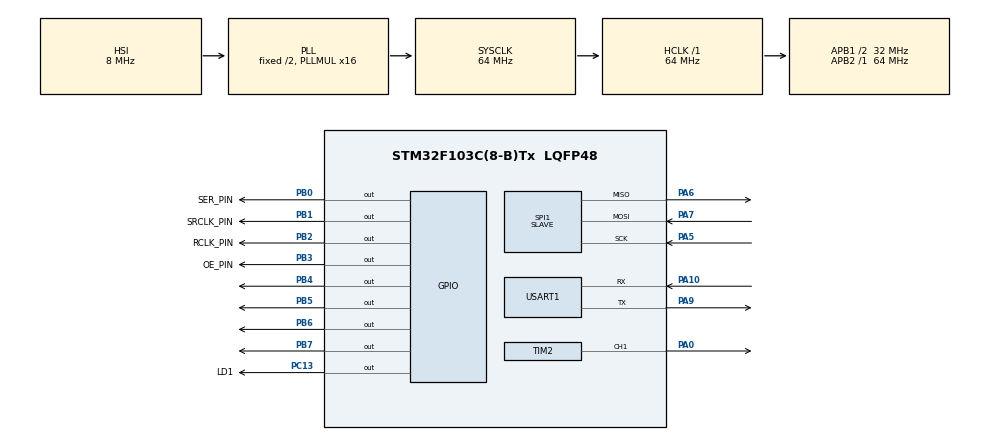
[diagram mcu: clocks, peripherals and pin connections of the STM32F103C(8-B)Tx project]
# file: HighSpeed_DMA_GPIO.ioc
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Dma.Request0=TIM2_UP
Dma.TIM2_UP.0.Direction=DMA_PERIPH_TO_MEMORY
Dma.TIM2_UP.0.Instance=DMA1_Channel2
Dma.TIM2_UP.0.MemDataAlignment=DMA_MDATAALIGN_WORD
Dma.TIM2_UP.0.MemInc=DMA_MINC_ENABLE
Dma.TIM2_UP.0.Mode=DMA_CIRCULAR
Dma.TIM2_UP.0.PeriphDataAlignment=DMA_PDATAALIGN_WORD
Dma.TIM2_UP.0.PeriphInc=DMA_PINC_DISABLE
Dma.TIM2_UP.0.Priority=DMA_PRIORITY_LOW
Mcu.Family=STM32F1
Mcu.Name=STM32F103C(8-B)Tx
Mcu.Package=LQFP48
Mcu.UserConstants=TIM1_PERIOD,512-1;TIM1_PRESCALER,0;TIM2_PERIOD,512-2;TIM2_PRESCALER,0
NVIC.DMA1_Channel2_IRQn=true\:0\:0\:false\:false\:true\:false\:true\:true
NVIC.PriorityGroup=NVIC_PRIORITYGROUP_4
PA0-WKUP.Signal=S_TIM2_CH1_ETR
PA10.Mode=Asynchronous
PA10.Signal=USART1_RX
PA13.Mode=Serial_Wire
PA13.Signal=SYS_JTMS-SWDIO
PA14.Mode=Serial_Wire
PA14.Signal=SYS_JTCK-SWCLK
PA5.Mode=Full_Duplex_Slave
PA5.Signal=SPI1_SCK
PA6.Mode=Full_Duplex_Slave
PA6.Signal=SPI1_MISO
PA7.Mode=Full_Duplex_Slave
PA7.Signal=SPI1_MOSI
PA9.Mode=Asynchronous
PA9.Signal=USART1_TX
PB0.GPIO_Label=SER_PIN
PB0.GPIO_Speed=GPIO_SPEED_FREQ_HIGH
PB0.Signal=GPIO_Output
PB1.GPIO_Label=SRCLK_PIN
PB1.GPIO_Speed=GPIO_SPEED_FREQ_HIGH
PB1.Signal=GPIO_Output
PB2.GPIO_Label=RCLK_PIN
PB2.GPIO_Speed=GPIO_SPEED_FREQ_HIGH
PB2.Signal=GPIO_Output
PB3.GPIO_Label=OE_PIN
PB3.GPIO_Speed=GPIO_SPEED_FREQ_HIGH
PB3.Signal=GPIO_Output
PB4.Signal=GPIO_Output
PB5.Signal=GPIO_Output
PB6.Signal=GPIO_Output
PB7.Signal=GPIO_Output
PC13-TAMPER-RTC.GPIO_Label=LD1
PC13-TAMPER-RTC.Signal=GPIO_Output
PD0-OSC_IN.Mode=HSE-External-Oscillator
PD0-OSC_IN.Signal=RCC_OSC_IN
PD1-OSC_OUT.Mode=HSE-External-Oscillator
PD1-OSC_OUT.Signal=RCC_OSC_OUT
ProjectManager.HeapSize=0x200
ProjectManager.StackSize=0x400
ProjectManager.TargetToolchain=STM32CubeIDE
RCC.AHBFreq_Value=64000000
RCC.APB1CLKDivider=RCC_HCLK_DIV2
RCC.APB1Freq_Value=32000000
RCC.APB1TimFreq_Value=64000000
RCC.APB2Freq_Value=64000000
RCC.APB2TimFreq_Value=64000000
RCC.HCLKFreq_Value=64000000
RCC.HSEDivPLL=RCC_HSE_PREDIV_DIV2
RCC.HSE_VALUE=16000000
RCC.PLLMUL=RCC_PLL_MUL16
RCC.SYSCLKFreq_VALUE=64000000
RCC.SYSCLKSource=RCC_SYSCLKSOURCE_PLLCLK
RCC.USBFreq_Value=64000000
SH.S_TIM2_CH1_ETR.0=TIM2_CH1,Output Compare1 CH1
SPI1.Direction=SPI_DIRECTION_2LINES
SPI1.Mode=SPI_MODE_SLAVE
SPI1.VirtualType=VM_SLAVE
TIM2.AutoReloadPreload=TIM_AUTORELOAD_PRELOAD_ENABLE
TIM2.Channel-Output\ Compare1\ CH1=TIM_CHANNEL_1
TIM2.OCMode_1=TIM_OCMODE_TOGGLE
TIM2.Period=TIM2_PERIOD
TIM2.Prescaler=TIM2_PRESCALER
TIM2.TIM_MasterOutputTrigger=TIM_TRGO_UPDATE
USART1.VirtualMode=VM_ASYNC
VP_TIM2_VS_ClockSourceINT.Mode=Internal
VP_TIM2_VS_ClockSourceITR.Mode=TriggerSource_ITR0
board=custom

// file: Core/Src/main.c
/* USER CODE BEGIN Header */
/**
  ******************************************************************************
  * @file           : main.c
  * @brief          : Main program body
  ******************************************************************************
  * @attention
  *
  * Copyright (c) 2024 STMicroelectronics.
  * All rights reserved.
  *
  * This software is licensed under terms that can be found in the LICENSE file
  * in the root directory of this software component.
  * If no LICENSE file comes with this software, it is provided AS-IS.
  *
  ******************************************************************************
  */
/* USER CODE END Header */
#include "main.h"
#include "dma.h"
#include "spi.h"
#include "tim.h"
#include "usart.h"
#include "gpio.h"

/* USER CODE BEGIN PD */
#undef TIM1_PERIOD
#define TIM1_PERIOD 1-1
/* USER CODE END PD */

/* USER CODE BEGIN PV */
extern DMA_HandleTypeDef hdma_tim2_up;

/* USER CODE END PV */

void SystemClock_Config(void);

int main(void)
{

  /* MCU Configuration--------------------------------------------------------*/

  /* Reset of all peripherals, Initializes the Flash interface and the Systick. */
  HAL_Init();

  /* Configure the system clock */
  SystemClock_Config();

  /* Initialize all configured peripherals */
  MX_GPIO_Init();
  MX_DMA_Init();
  MX_SPI1_Init();
  MX_USART1_UART_Init();
  MX_TIM2_Init();
  /* USER CODE BEGIN 2 */

  // uint32_t pixelclock[8] = {0x00000000, 0xffffffff, 0xffffffff, 0x0000, 0x00, 0x00, 0xffffffff, 0x00};
   uint32_t pixelclock[16];
   for(int i=0;i<16;i++)
 	  pixelclock[i]=0;
   // the pixelclock goes straight to the BSRR register
   // [31 ... 16] are reset bits corresponding to Ports [15 ... 0]
   // [15 ...  0] are   set bits corresponding to Ports [15 ... 0]
   // if a reset bit is set, the GPIO port will be set LOW
   // if a   set bit is set, the GPIO port will be set HIGH
   pixelclock[ 0] = 0x00000001;  // set SI signal on 1st clock edge
   pixelclock[ 2] = 0x00010000;  // reset SI signal on 3rd clock edge
   pixelclock[ 9] = 0x00000002;  // set the ESH signal high
   pixelclock[13] = 0x00020000;  // set the ESH signal low

   // DMA, circular memory-to-peripheral mode, full word (32 bit) transfer
   HAL_DMA_Start(&hdma_tim2_up,  (uint32_t)pixelclock, (uint32_t)&(GPIOB->BSRR), 16);
   HAL_TIM_Base_Start(&htim2);
   HAL_TIM_OC_Start(&htim2, TIM_CHANNEL_1);
   TIM2->DIER |= (1 << 8);   // set UDE bit (update dma request enable)

  /* USER CODE END 2 */

  /* Infinite loop */
  while (1)
  {

  }
}

void SystemClock_Config(void)
{
  RCC_OscInitTypeDef RCC_OscInitStruct = {0};
  RCC_ClkInitTypeDef RCC_ClkInitStruct = {0};

  /** Initializes the RCC Oscillators according to the specified parameters
  * in the RCC_OscInitTypeDef structure.
  */
  RCC_OscInitStruct.OscillatorType = RCC_OSCILLATORTYPE_HSI;
  RCC_OscInitStruct.HSIState = RCC_HSI_ON;
  RCC_OscInitStruct.HSICalibrationValue = RCC_HSICALIBRATION_DEFAULT;
  RCC_OscInitStruct.PLL.PLLState = RCC_PLL_ON;
  RCC_OscInitStruct.PLL.PLLSource = RCC_PLLSOURCE_HSI_DIV2;
  RCC_OscInitStruct.PLL.PLLMUL = RCC_PLL_MUL16;
  if (HAL_RCC_OscConfig(&RCC_OscInitStruct) != HAL_OK)
  {
    Error_Handler();
  }

  /** Initializes the CPU, AHB and APB buses clocks
  */
  RCC_ClkInitStruct.ClockType = RCC_CLOCKTYPE_HCLK|RCC_CLOCKTYPE_SYSCLK
                              |RCC_CLOCKTYPE_PCLK1|RCC_CLOCKTYPE_PCLK2;
  RCC_ClkInitStruct.SYSCLKSource = RCC_SYSCLKSOURCE_PLLCLK;
  RCC_ClkInitStruct.AHBCLKDivider = RCC_SYSCLK_DIV1;
  RCC_ClkInitStruct.APB1CLKDivider = RCC_HCLK_DIV2;
  RCC_ClkInitStruct.APB2CLKDivider = RCC_HCLK_DIV1;

  if (HAL_RCC_ClockConfig(&RCC_ClkInitStruct, FLASH_LATENCY_2) != HAL_OK)
  {
    Error_Handler();
  }
}

/* USER CODE BEGIN 4 */
///**
//  * @brief  DMA conversion complete callback
//  * @note   This function is executed when the transfer complete interrupt
//  *         is generated at each end of DMA buffer
//  * @retval None
//  */
//static void TransferComplete(DMA_HandleTypeDef *DmaHandle)
//{
//  uint32_t tmp_ct = 0;
//  uint32_t tmp_mar = 0;
//
//  tmp_ct = ((hdma_tim2_up.hdma[TIMx_DMA_ID]->Instance->CR) & DMA_SxCR_CT);
//  /* Update memory 0 address location */
//  if (tmp_ct != 0)
//  {
//    tmp_mar = hdma_tim2_up->Instance->CMAR;
//    HAL_DMAEx_ChangeMemory(TimHandlex.hdma[TIMx_DMA_ID], (tmp_mar + (2*DMA_MEM_BUFF_SIZE)), MEMORY0);
//  }
//  /* Update memory 1 address location */
//  else
//  {
//    tmp_mar = hdma_tim2_up.hdma[TIMx_DMA_ID]->Instance->M1AR;
//    HAL_DMAEx_ChangeMemory(TimHandlex.hdma[TIMx_DMA_ID], (tmp_mar + (2*DMA_MEM_BUFF_SIZE)), MEMORY1);
//  }
//
//}

/* USER CODE END 4 */

void Error_Handler(void)
{
  __disable_irq();
  while (1)
  {
  }
}
